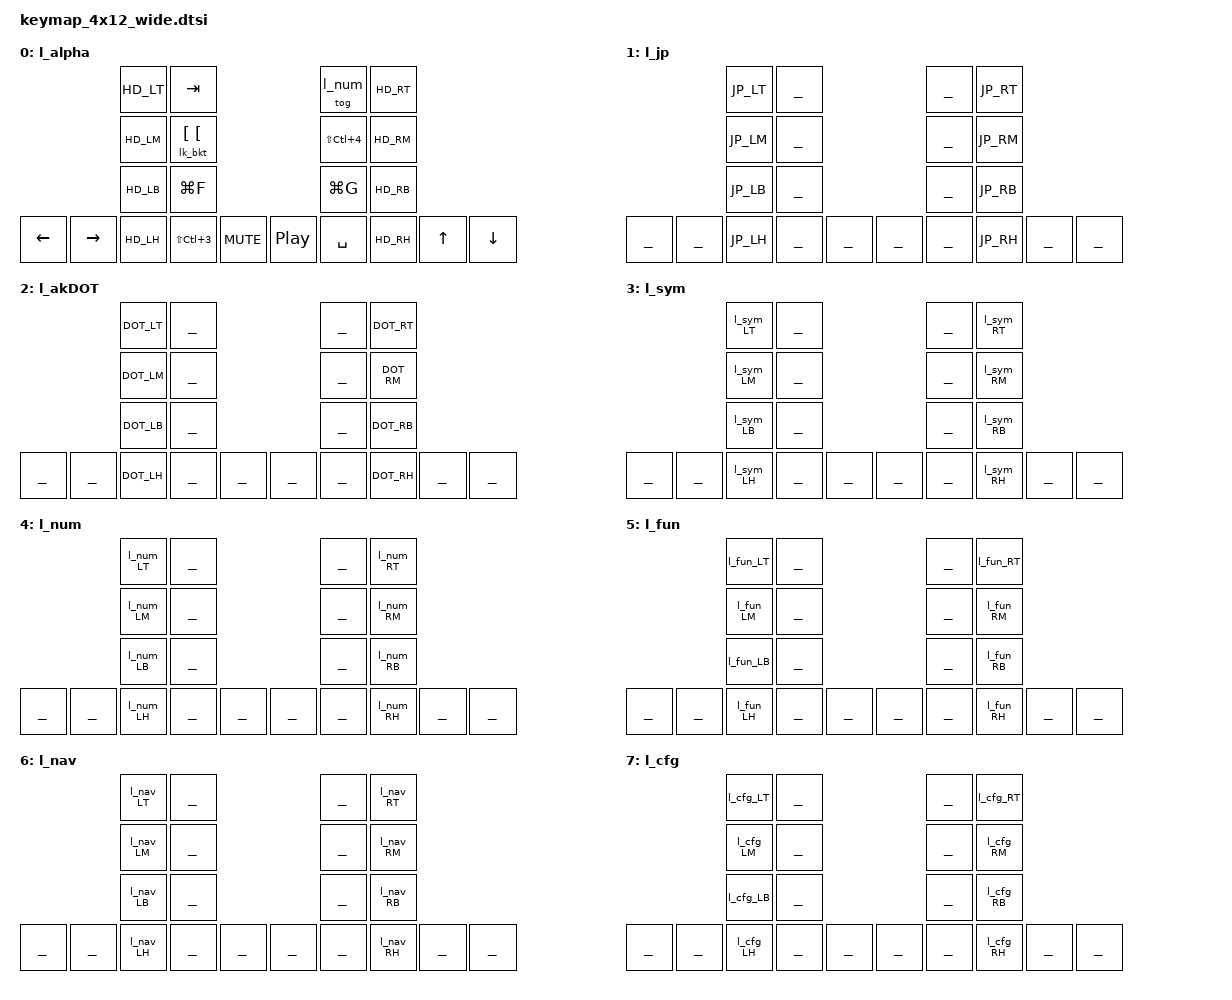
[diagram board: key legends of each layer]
/*
    Assemble the keymap from the abstracted alpha layer and other layers
    
    This is for a 12x4 (48 key) ortholinear board
    
    Works with Planck, Naked48, etc.
        
    Uses the core 3x5+2 alpha row defs and adds extra keys to fill out the keymap.
    The key (rows) values are defined in the corresponding HD-##.h file
    that should be included in the .keymap file before this.

    Layers are defined in moutis_config.dtsi so they can be
    referenced anywhere (keymap, behaviors, combos, adaptives)

    I prefer a "Wide Planck" layout (no keys outside of pinky)
    to separate the hands and reduce wrist splay
*/

#include "layers_def.h" // layer def common core (3x5+2)

    keymap {
        compatible = "zmk,keymap";
            l_alpha {
                label = HD_Layer_label;
                bindings = <
                                    HD_LT   &kp TAB                         &tog l_num      HD_RT
                                    HD_LM   &lk_bkt LBKT LBKT               &kp LS(LC(N4))  HD_RM
                                    HD_LB   &kp LG(F)                       &kp LG(G)       HD_RB
                &kp LEFT &kp RIGHT  HD_LH   &kp LS(LC(N3)) &kp C_MUTE  &kp C_PP  &kp SPACE  HD_RH   &kp UP  &kp DOWN
                >;
            };
            l_jp {
                label = JP_Layer_label;
                bindings = <
                                    JP_LT       _______                     _______     JP_RT
                                    JP_LM       _______                     _______     JP_RM
                                    JP_LB       _______                     _______     JP_RB
                _______ _______     JP_LH       _______ _______     _______ _______     JP_RH       _______ _______
                >;
            };
            l_akDOT {
                label = l_akDOT_label;
                bindings = <
                                    DOT_LT      _______                     _______     DOT_RT
                                    DOT_LM      _______                     _______     DOT_RM
                                    DOT_LB      _______                     _______     DOT_RB
                _______ _______     DOT_LH      _______ _______     _______ _______     DOT_RH      _______ _______
                >;
            };

            l_sym {
            label = l_sym_label;
                bindings = <
                                    l_sym_LT    _______                     _______     l_sym_RT
                                    l_sym_LM    _______                     _______     l_sym_RM
                                    l_sym_LB    _______                     _______     l_sym_RB
                _______ _______     l_sym_LH    _______ _______     _______ _______     l_sym_RH    _______ _______
                >;
            };

            l_num {
                label = l_num_label;
                bindings = <
                                    l_num_LT   _______                      _______     l_num_RT
                                    l_num_LM   _______                      _______     l_num_RM
                                    l_num_LB   _______                      _______     l_num_RB
                _______ _______     l_num_LH   _______ _______      _______ _______     l_num_RH    _______ _______
                >;
            };

            l_fun {
                label = l_fun_label;
                bindings = <
                                    l_fun_LT    _______                     _______     l_fun_RT
                                    l_fun_LM    _______                     _______     l_fun_RM
                                    l_fun_LB    _______                     _______     l_fun_RB
                _______ _______     l_fun_LH    _______ _______     _______ _______     l_fun_RH    _______ _______
                >;
            };

            l_nav {
                label = l_nav_label;
                bindings = <
                                    l_nav_LT    _______                     _______     l_nav_RT
                                    l_nav_LM    _______                     _______     l_nav_RM
                                    l_nav_LB    _______                     _______     l_nav_RB
                _______ _______     l_nav_LH    _______ _______     _______ _______     l_nav_RH    _______ _______
                >;
            };

            l_cfg {
                label = l_cfg_label;
                bindings = <
                                    l_cfg_LT    _______                     _______     l_cfg_RT
                                    l_cfg_LM    _______                     _______     l_cfg_RM
                                    l_cfg_LB    _______                     _______     l_cfg_RB
                _______ _______     l_cfg_LH    _______ _______     _______ _______     l_cfg_RH    _______ _______
                >;
            };
   
    };
